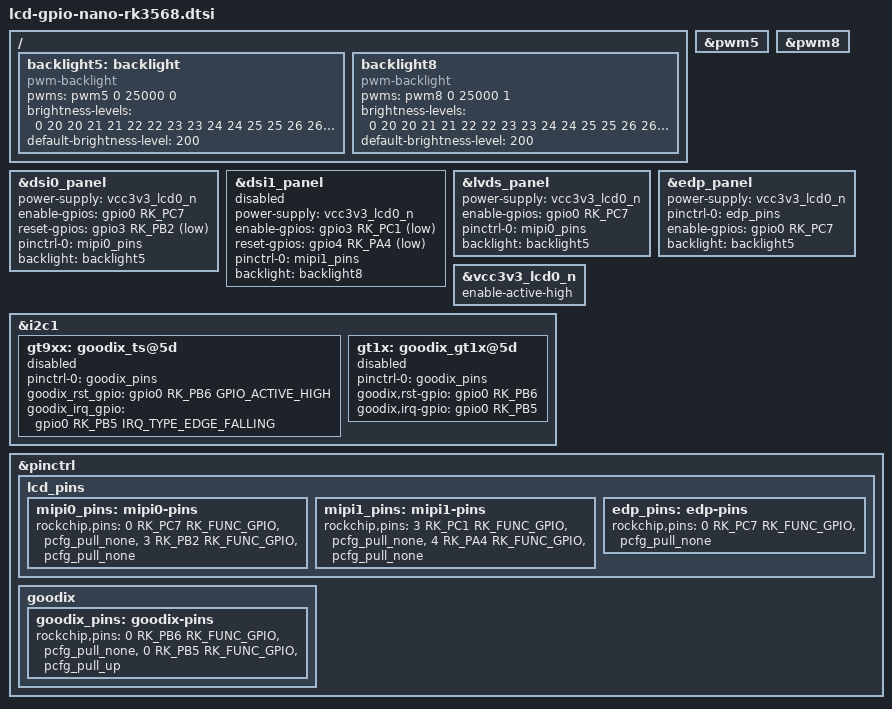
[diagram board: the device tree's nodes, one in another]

/ {	
	backlight5: backlight {
		compatible = "pwm-backlight";
		pwms = <&pwm5 0 25000 0>;
		brightness-levels = <
			  0  20  20  21  21  22  22  23
			 23  24  24  25  25  26  26  27
			 27  28  28  29  29  30  30  31
			 31  32  32  33  33  34  34  35
			 35  36  36  37  37  38  38  39
			 40  41  42  43  44  45  46  47
			 48  49  50  51  52  53  54  55
			 56  57  58  59  60  61  62  63
			 64  65  66  67  68  69  70  71
			 72  73  74  75  76  77  78  79
			 80  81  82  83  84  85  86  87
			 88  89  90  91  92  93  94  95
			 96  97  98  99 100 101 102 103
			104 105 106 107 108 109 110 111
			112 113 114 115 116 117 118 119
			120 121 122 123 124 125 126 127
			128 129 130 131 132 133 134 135
			136 137 138 139 140 141 142 143
			144 145 146 147 148 149 150 151
			152 153 154 155 156 157 158 159
			160 161 162 163 164 165 166 167
			168 169 170 171 172 173 174 175
			176 177 178 179 180 181 182 183
			184 185 186 187 188 189 190 191
			192 193 194 195 196 197 198 199
			200 201 202 203 204 205 206 207
			208 209 210 211 212 213 214 215
			216 217 218 219 220 221 222 223
			224 225 226 227 228 229 230 231
			232 233 234 235 236 237 238 239
			240 241 242 243 244 245 246 247
			248 249 250 251 252 253 254 255
		>;
		default-brightness-level = <200>;
	};
	
	backlight8: backlight8 {
		compatible = "pwm-backlight";
		pwms = <&pwm8 0 25000 1>;
		brightness-levels = <
			  0  20  20  21  21  22  22  23
			 23  24  24  25  25  26  26  27
			 27  28  28  29  29  30  30  31
			 31  32  32  33  33  34  34  35
			 35  36  36  37  37  38  38  39
			 40  41  42  43  44  45  46  47
			 48  49  50  51  52  53  54  55
			 56  57  58  59  60  61  62  63
			 64  65  66  67  68  69  70  71
			 72  73  74  75  76  77  78  79
			 80  81  82  83  84  85  86  87
			 88  89  90  91  92  93  94  95
			 96  97  98  99 100 101 102 103
			104 105 106 107 108 109 110 111
			112 113 114 115 116 117 118 119
			120 121 122 123 124 125 126 127
			128 129 130 131 132 133 134 135
			136 137 138 139 140 141 142 143
			144 145 146 147 148 149 150 151
			152 153 154 155 156 157 158 159
			160 161 162 163 164 165 166 167
			168 169 170 171 172 173 174 175
			176 177 178 179 180 181 182 183
			184 185 186 187 188 189 190 191
			192 193 194 195 196 197 198 199
			200 201 202 203 204 205 206 207
			208 209 210 211 212 213 214 215
			216 217 218 219 220 221 222 223
			224 225 226 227 228 229 230 231
			232 233 234 235 236 237 238 239
			240 241 242 243 244 245 246 247
			248 249 250 251 252 253 254 255
		>;
		default-brightness-level = <200>;
	};
};

&pwm5 {
	status = "okay";
};

&pwm8 {
    status = "okay";
};

// MIPI DSI0 
&dsi0_panel {
	power-supply = <&vcc3v3_lcd0_n>;
    	enable-gpios = <&gpio0 RK_PC7 GPIO_ACTIVE_HIGH>;
	reset-gpios = <&gpio3 RK_PB2 GPIO_ACTIVE_LOW>;
	pinctrl-names = "default";
	pinctrl-0 = <&mipi0_pins>;
	backlight = <&backlight5>;
};

// MIPI1toLVDS
&dsi1_panel {
    	status = "disabled";
    	power-supply = <&vcc3v3_lcd0_n>;
        enable-gpios = <&gpio3 RK_PC1 GPIO_ACTIVE_LOW>; //raw interface is inverse, so set to low
	reset-gpios = <&gpio4 RK_PA4 GPIO_ACTIVE_LOW>;
        pinctrl-names = "default";
        pinctrl-0 = <&mipi1_pins>;
        backlight = <&backlight8>;
};

// LVDS
&lvds_panel {
        power-supply = <&vcc3v3_lcd0_n>;
    	enable-gpios = <&gpio0 RK_PC7 GPIO_ACTIVE_HIGH>; 
        // reset-gpios = <&gpio3 RK_PB2 GPIO_ACTIVE_LOW>;
        pinctrl-names = "default";
        pinctrl-0 = <&mipi0_pins>;
        backlight = <&backlight5>;
};

// EDP
&edp_panel {
	power-supply = <&vcc3v3_lcd0_n>;
    	pinctrl-names = "default";
    	pinctrl-0 = <&edp_pins>;
    	enable-gpios = <&gpio0 RK_PC7 GPIO_ACTIVE_HIGH>;
	backlight = <&backlight5>;
};


// POWER GPIO
&vcc3v3_lcd0_n {
	// gpio = <&gpio0 RK_PC7 GPIO_ACTIVE_HIGH>;
    /delete-property/ gpio;
	enable-active-high;
};

// TP
&i2c1 {
    gt9xx: goodix_ts@5d {
        /***** tp pin ******/
        pinctrl-names = "default";
        pinctrl-0 = <&goodix_pins>;
        goodix_rst_gpio = <&gpio0 RK_PB6 GPIO_ACTIVE_HIGH>;
        goodix_irq_gpio = <&gpio0 RK_PB5 IRQ_TYPE_EDGE_FALLING>;
        
        status = "disabled";
    };
    gt1x: goodix_gt1x@5d {
        /***** tp pin ******/
        pinctrl-names = "default";
        pinctrl-0 = <&goodix_pins>;
        goodix,rst-gpio = <&gpio0 RK_PB6 GPIO_ACTIVE_HIGH>;
        goodix,irq-gpio = <&gpio0 RK_PB5 IRQ_TYPE_EDGE_FALLING>;
        
        status = "disabled";
    };
};

&pinctrl {
	lcd_pins {
		mipi0_pins: mipi0-pins {
			rockchip,pins =
                /** mipi0 enable */
                <0 RK_PC7 RK_FUNC_GPIO &pcfg_pull_none>,
                /** mipi0 reset */
                <3 RK_PB2 RK_FUNC_GPIO &pcfg_pull_none>;
		};

		mipi1_pins: mipi1-pins {
                        rockchip,pins =	
		/** mipi1 enable */
                <3 RK_PC1 RK_FUNC_GPIO &pcfg_pull_none>,
                /** mipi1 reset */
                <4 RK_PA4 RK_FUNC_GPIO &pcfg_pull_none>;
	        };

        	edp_pins: edp-pins {
			rockchip,pins =
                /** edp enable */
                <0 RK_PC7 RK_FUNC_GPIO &pcfg_pull_none>;
        	};
	};
    
	goodix {
		goodix_pins: goodix-pins {
			rockchip,pins =
                /** rst pin */
                <0 RK_PB6 RK_FUNC_GPIO &pcfg_pull_none>,
                /** irq pin */
		<0 RK_PB5 RK_FUNC_GPIO &pcfg_pull_up>;
		};
	};
};


